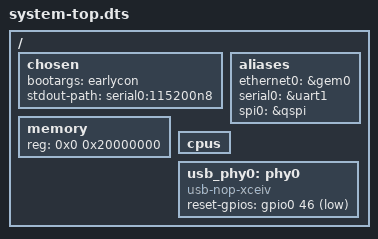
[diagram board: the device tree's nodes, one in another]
/*
 * CAUTION: This file is automatically generated by Xilinx.
 * Version:  
 * Today is: Sun Mar  4 17:06:06 2018
 */


/dts-v1/;
/include/ "zynq-7000.dtsi"
/include/ "pl.dtsi"
/include/ "pcw.dtsi"
/ {
	chosen {
		bootargs = "earlycon";
		stdout-path = "serial0:115200n8";
	};
	aliases {
		ethernet0 = &gem0;
		serial0 = &uart1;
		spi0 = &qspi;
	};
	memory {
		device_type = "memory";
		reg = <0x0 0x20000000>;
	};
	cpus {
	};
    usb_phy0: phy0 {
   		    #phy-cells = <0>;
     		compatible = "usb-nop-xceiv";
      	    reset-gpios = <&gpio0 46 1>;
    };

};
